AUTOSAR XML (schema 00048)
package /AdaptiveApplicationSwComponentTypes
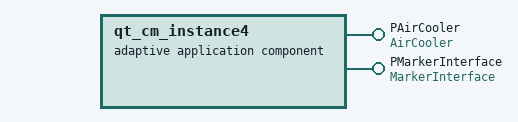
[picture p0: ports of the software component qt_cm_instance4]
  adaptive application sw component type qt_cm_instance4
    provide port PAirCooler: provided-interface=AirCooler
    provide port PMarkerInterface: provided-interface=MarkerInterface
package /Executables
  executable qt_cm_instance4
    root sw component prototype rootSwComponentPrototype: application-type=qt_cm_instance4
